AUTOSAR XML (schema 4-0-3)
package /ComponentTypes
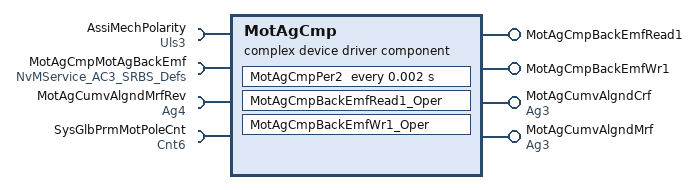
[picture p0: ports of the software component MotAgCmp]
  complex device driver sw component type MotAgCmp
    4 x provide port:
      MotAgCmpBackEmfRead1: server-com-spec{operation=Oper, queue-length=1}, provided-interface=MotAgCmpBackEmfRead1
      MotAgCmpBackEmfWr1: server-com-spec{operation=Oper, queue-length=1}, provided-interface=MotAgCmpBackEmfWr1
      MotAgCumvAlgndCrf: nonqueued-sender-com-spec{data-element=Val, init-value=0}, provided-interface=Ag3
      MotAgCumvAlgndMrf: nonqueued-sender-com-spec{data-element=Val, init-value=0}, provided-interface=Ag3
    4 x require port:
      AssiMechPolarity: nonqueued-receiver-com-spec{data-element=Val, filter=data-filter-type=ALWAYS, init-value=1}, required-interface=Uls3
      MotAgCmpMotAgBackEmf: required-interface=NvMService_AC3_SRBS_Defs
      MotAgCumvAlgndMrfRev: nonqueued-receiver-com-spec{data-element=Val, filter=data-filter-type=ALWAYS, init-value=0}, required-interface=Ag4
      SysGlbPrmMotPoleCnt: parameter-require-com-spec{init-value=6, parameter=Val}, required-interface=Cnt6
    behavior MotAgCmp_InternalBehavior: data-type-mapping=Nexteer
      ar-typed-per-instance-memorys:
        4 x data, all with sw-calibration-access=READ-ONLY:
          MotAgCmpFirstRunCmpl: type=Logl1
          MotAgCmpMotAgBackEmf_MirrorBlock: type=Ag9
          MotAgCmpMotCtrlMotAgCumvAlgndMrfRevSVPrev: type=Ag8
          MotAgCmpMotCtrlMotAgMeclPrev: type=Ag8
      operation invoked event OIT_MotAgCmpBackEmfRead1_Oper_MotAgCmpBackEmfRead1_Oper: start-on-event=MotAgCmpBackEmfRead1_Oper, operation=MotAgCmpBackEmfRead1.Oper
      operation invoked event OIT_MotAgCmpBackEmfWr1_Oper_MotAgCmpBackEmfWr1_Oper: start-on-event=MotAgCmpBackEmfWr1_Oper, operation=MotAgCmpBackEmfWr1.Oper
      timing event TMT_MotAgCmpPer2: start-on-event=MotAgCmpPer2, period=0.002
      runnable MotAgCmpBackEmfRead1_Oper
        sync call SC_MotAgCmpMotAgBackEmf_ReadBlock: operation=MotAgCmpMotAgBackEmf.ReadBlock, timeout=0
      runnable MotAgCmpBackEmfWr1_Oper
        sync call SC_MotAgCmpMotAgBackEmf_SetRamBlockStatus: operation=MotAgCmpMotAgBackEmf.SetRamBlockStatus, timeout=0
      runnable MotAgCmpPer2
        data-receive-point-by-arguments:
          access REC_AssiMechPolarity_Val: accessed-variable=AssiMechPolarity.Val
          access REC_MotAgCumvAlgndMrfRev_Val: accessed-variable=MotAgCumvAlgndMrfRev.Val
        data-send-points:
          access SEND_MotAgCumvAlgndCrf_Val: accessed-variable=MotAgCumvAlgndCrf.Val
          access SEND_MotAgCumvAlgndMrf_Val: accessed-variable=MotAgCumvAlgndMrf.Val
      swc service dependency MotAgCmpMotAgBackEmf: assigned-ports=role-based-port-assignment={port-prototype=MotAgCmpMotAgBackEmf, role=NvMService_AC3_SRBS_DS}
        assigned-datas:
          role=ramBlock, used-data-element=MotAgCmpMotAgBackEmf_MirrorBlock
          role=defaultValue, used-parameter-element=MotAgCmpMotAgBackEmf_DefaultValue
        service-needs:
          nv block needs MotAgCmpMotAgBackEmf: n-data-sets=0, readonly=false, reliability=ERROR-DETECTION, resistant-to-changed-sw=true, restore-at-start=true, store-at-shutdown=true, write-only-once=false, writing-frequency=0, writing-priority=LOW
      shared-parameters:
        parameter data prototype MotAgCmpMotAgBackEmf_DefaultValue: sw-calibration-access=READ-WRITE, type=Ag9, init-value=0
  swc implementation MotAgCmp_Implementation: behavior=MotAgCmp_InternalBehavior
    code-descriptors:
      code Default: artifact-descriptors=autosar-engineering-object={short-label=Default, category=SWSRC}
